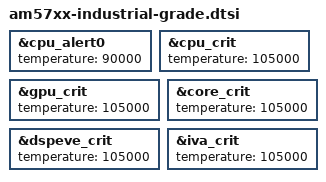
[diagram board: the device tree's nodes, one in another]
&cpu_alert0 {
	temperature = <90000>; /* milliCelsius */
};

&cpu_crit {
	temperature = <105000>; /* milliCelsius */
};

&gpu_crit {
	temperature = <105000>; /* milliCelsius */
};

&core_crit {
	temperature = <105000>; /* milliCelsius */
};

&dspeve_crit {
	temperature = <105000>; /* milliCelsius */
};

&iva_crit {
	temperature = <105000>; /* milliCelsius */
};
